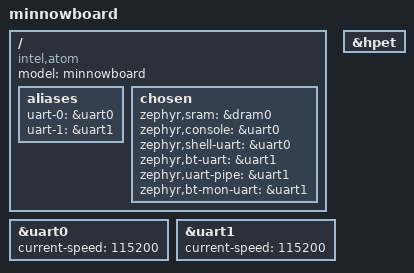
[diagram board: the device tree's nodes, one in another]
/* SPDX-License-Identifier: Apache-2.0 */

/dts-v1/;

#include <mem.h>

#define DT_DRAM_SIZE		DT_SIZE_M(2048)

#include <atom.dtsi>

/ {
	model = "minnowboard";
	compatible = "intel,atom";

	aliases {
		uart-0 = &uart0;
		uart-1 = &uart1;
	};

	chosen {
		zephyr,sram = &dram0;
		zephyr,console = &uart0;
		zephyr,shell-uart = &uart0;
		zephyr,bt-uart = &uart1;
		zephyr,uart-pipe = &uart1;
		zephyr,bt-mon-uart = &uart1;
	};
};

&uart0 {
	status = "okay";
	current-speed = <115200>;
};

&uart1 {
	status = "okay";
	current-speed = <115200>;
};

&hpet {
	status = "okay";
};
